VERSION "HIPBYYYYYYYYYYYYYYYYYYYYYYYYYYYYNNNNNNNNNN/4/%%%/4/'%**4NNN///"

NS_ :

BS_:

BU_: SMotion

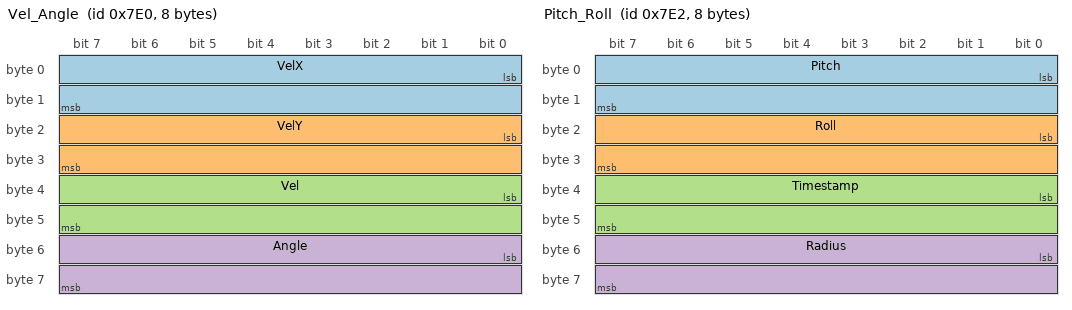
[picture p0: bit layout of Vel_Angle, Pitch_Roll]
BO_ 2016 Vel_Angle: 8 SMotion
 SG_ VelX : 0|16@1- (0.036,0) [-400|400] "km/h" SMotion
 SG_ VelY : 16|16@1- (0.036,0) [-100|100] "km/h" SMotion
 SG_ Vel : 32|16@1- (0.036,0) [-400|400] "km/h" SMotion
 SG_ Angle : 48|16@1- (0.01,0) [-45|45] "°" SMotion

BO_ 2017 Distance: 4 SMotion
 SG_ Distance : 0|32@1- (0.001,0) [-2.14748e+06|2.14748e+06] "m" SMotion

BO_ 2018 Pitch_Roll: 8 SMotion
 SG_ Pitch : 0|16@1- (0.01,0) [-45|45] "°" SMotion
 SG_ Roll : 16|16@1- (0.01,0) [-45|45] "°" SMotion
 SG_ Timestamp : 32|16@1+ (1,0) [0|65535] "" SMotion
 SG_ Radius : 48|16@1+ (0.01,0) [0|655.35] "m" SMotion

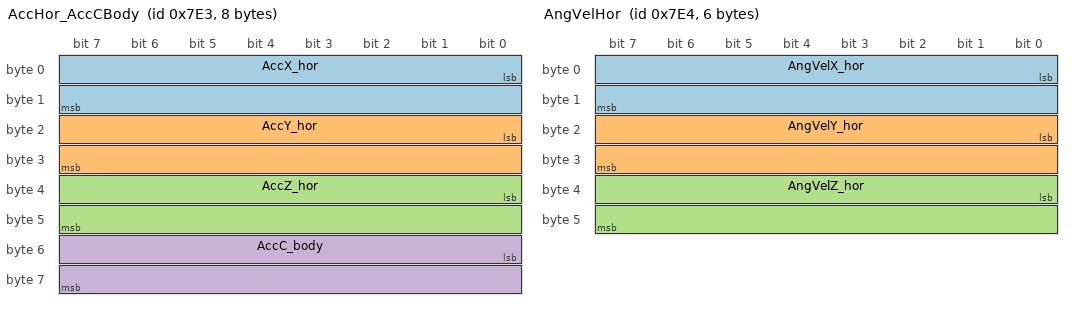
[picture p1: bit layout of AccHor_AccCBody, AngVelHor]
BO_ 2019 AccHor_AccCBody: 8 SMotion
 SG_ AccX_hor : 0|16@1- (0.01,0) [-180|180] "m/s²" SMotion
 SG_ AccY_hor : 16|16@1- (0.01,0) [-180|180] "m/s²" SMotion
 SG_ AccZ_hor : 32|16@1- (0.01,0) [-180|180] "m/s²" SMotion
 SG_ AccC_body : 48|16@1- (0.01,0) [-180|180] "m/s²" SMotion

BO_ 2020 AngVelHor: 6 SMotion
 SG_ AngVelX_hor : 0|16@1- (0.02,0) [-300|300] "°/s" SMotion
 SG_ AngVelY_hor : 16|16@1- (0.02,0) [-300|300] "°/s" SMotion
 SG_ AngVelZ_hor : 32|16@1- (0.02,0) [-300|300] "°/s" SMotion

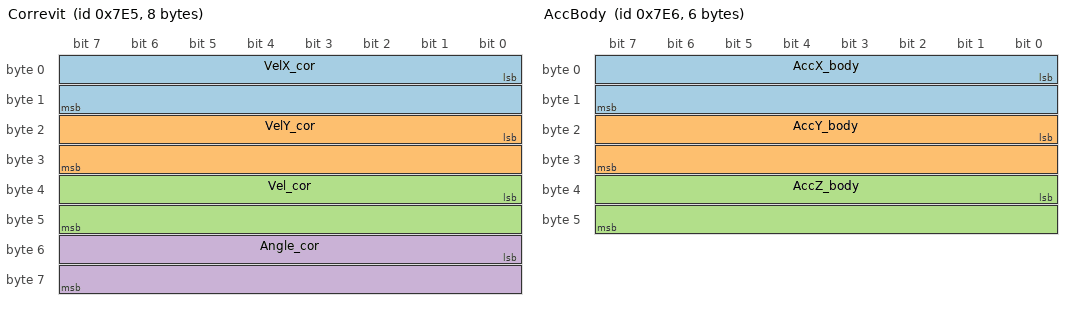
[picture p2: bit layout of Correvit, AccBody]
BO_ 2021 Correvit: 8 SMotion
 SG_ VelX_cor : 0|16@1- (0.036,0) [-400|400] "km/h" SMotion
 SG_ VelY_cor : 16|16@1- (0.036,0) [-100|100] "km/h" SMotion
 SG_ Vel_cor : 32|16@1- (0.036,0) [-400|400] "km/h" SMotion
 SG_ Angle_cor : 48|16@1- (0.01,0) [-45|45] "°" SMotion

BO_ 2022 AccBody: 6 SMotion
 SG_ AccX_body : 0|16@1- (0.01,0) [-180|180] "m/s²" SMotion
 SG_ AccY_body : 16|16@1- (0.01,0) [-180|180] "m/s²" SMotion
 SG_ AccZ_body : 32|16@1- (0.01,0) [-180|180] "m/s²" SMotion

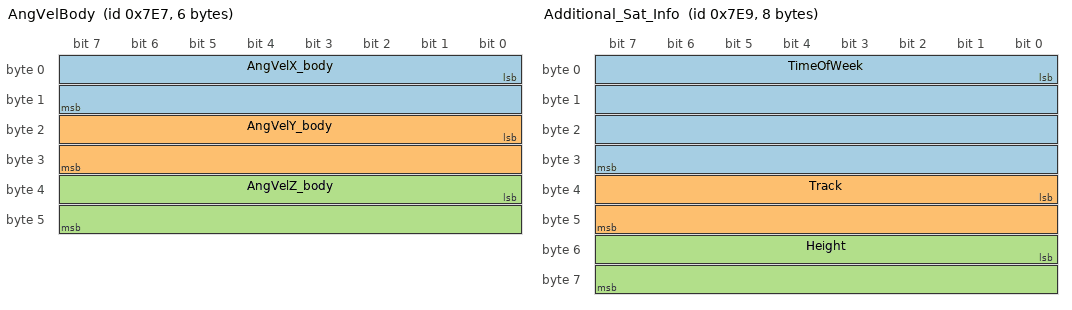
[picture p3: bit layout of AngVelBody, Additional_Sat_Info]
BO_ 2023 AngVelBody: 6 SMotion
 SG_ AngVelX_body : 0|16@1- (0.02,0) [-300|300] "°/s" SMotion
 SG_ AngVelY_body : 16|16@1- (0.02,0) [-300|300] "°/s" SMotion
 SG_ AngVelZ_body : 32|16@1- (0.02,0) [-300|300] "°/s" SMotion

BO_ 2024 Coordinates: 8 SMotion
 SG_ Latitude : 0|32@1- (1e-07,0) [-90|90] "°" SMotion
 SG_ Longitude : 32|32@1- (1e-07,0) [-180|180] "°" SMotion

BO_ 2025 Additional_Sat_Info: 8 SMotion
 SG_ TimeOfWeek : 0|32@1+ (1,0) [0|6.048e+08] "ms" SMotion
 SG_ Track : 32|16@1+ (0.01,0) [0|360] "°" SMotion
 SG_ Height : 48|16@1- (1,0) [-500|9000] "m" SMotion

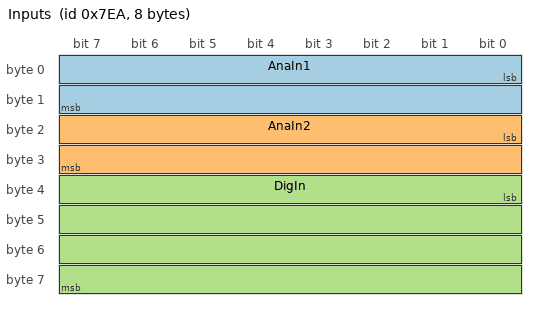
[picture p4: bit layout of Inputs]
BO_ 2026 Inputs: 8 SMotion
 SG_ AnaIn1 : 0|16@1- (0.001,0) [-10|10] "V" SMotion
 SG_ AnaIn2 : 16|16@1- (0.001,0) [-10|10] "V" SMotion
 SG_ DigIn : 32|32@1+ (1,0) [0|4.29497e+09] "" SMotion

BO_ 2027 Status: 8 SMotion
 SG_ SensorID : 0|16@1+ (1,0) [0|9999] "" SMotion
 SG_ Temperature : 16|8@1- (1,0) [-128|127] "°C" SMotion
 SG_ LampCurrent : 24|8@1+ (0.01,0) [0|2.55] "A" SMotion
 SG_ FilterSetting : 32|8@1+ (1,0) [0|255] "" SMotion
 SG_ NumOfSat : 40|8@1+ (1,0) [0|255] "" SMotion
 SG_ STST : 48|1@1+ (1,0) [0|1] "" SMotion
 SG_ FilterOffOn : 49|1@1+ (1,0) [0|1] "" SMotion
 SG_ LampCurrentControl : 50|1@1+ (1,0) [0|1] "" SMotion
 SG_ TemperatureOK : 51|1@1+ (1,0) [0|1] "" SMotion
 SG_ HeadStatus : 52|2@1+ (1,0) [0|3] "" SMotion
 SG_ AngleSwitchedOff : 54|1@1+ (1,0) [0|1] "" SMotion
 SG_ Direction : 55|1@1+ (1,0) [0|1] "" SMotion
 SG_ SatFixed : 56|1@1+ (1,0) [0|1] "" SMotion
 SG_ AngVelCorrection : 57|1@1+ (1,0) [0|1] "" SMotion
 SG_ DirectionMotion : 58|1@1+ (1,0) [0|1] "" SMotion
 SG_ DirectionMounting : 59|1@1+ (1,0) [0|1] "" SMotion
 SG_ DirectionHeadIsValid : 60|1@1+ (1,0) [0|1] "" SMotion
 SG_ DirectionHead : 61|1@1+ (1,0) [0|1] "" SMotion
